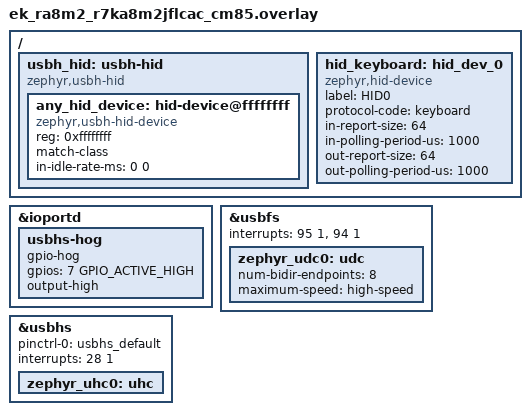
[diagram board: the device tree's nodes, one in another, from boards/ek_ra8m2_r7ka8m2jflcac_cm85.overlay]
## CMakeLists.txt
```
# Copyright (c) 2026 Renesas Electronics Corporation
# SPDX-License-Identifier: Apache-2.0

cmake_minimum_required(VERSION 3.20.0)

find_package(Zephyr REQUIRED HINTS $ENV{ZEPHYR_BASE})
project(test_usbh_hid)

include(${ZEPHYR_BASE}/samples/subsys/usb/common/common.cmake)

target_include_directories(app PRIVATE ${ZEPHYR_BASE}/tests/subsys/usb/host/common)
target_include_directories(app PRIVATE ${ZEPHYR_BASE}/subsys/usb/host)

target_sources(app PRIVATE src/keyboard.c src/hid_keyboard.c)
```

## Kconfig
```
# SPDX-FileCopyrightText: Copyright The Zephyr Project Contributors
# SPDX-License-Identifier: Apache-2.0

config SYS_CLOCK_TICKS_PER_SEC
	default 1000000 if BOARD_NATIVE_SIM

source "samples/subsys/usb/common/Kconfig.sample_usbd"

source "Kconfig.zephyr"
```

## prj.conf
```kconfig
CONFIG_LOG=y
CONFIG_ZTEST=y

CONFIG_USB_DEVICE_STACK_NEXT=y
CONFIG_USBD_HID_SUPPORT=y
CONFIG_UDC_ENABLE_SOF=y
CONFIG_SAMPLE_USBD_PID=0xFFFF

CONFIG_UHC_DRIVER=y
CONFIG_USB_HOST_STACK=y
```

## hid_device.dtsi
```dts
/*
 * SPDX-FileCopyrightText: Copyright The Zephyr Project Contributors
 * SPDX-License-Identifier: Apache-2.0
 */

/ {
	hid_dev_0: hid_dev_0 {
		compatible = "zephyr,hid-device";
		protocol-code = "none";
		in-report-size = <6>;
		in-polling-period-us = <1000>;
		/* Intentionally not a multiple of the UDC buffer granularity */
		out-report-size = <6>;
		out-polling-period-us = <1000>;
	};
};
```

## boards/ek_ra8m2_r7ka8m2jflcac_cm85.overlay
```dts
/*
 * Copyright (c) 2026 Renesas Electronics Corporation
 *
 *
 * SPDX-License-Identifier: Apache-2.0
 */

/delete-node/ &zephyr_udc0;

/ {
	usbh_hid: usbh-hid {
		compatible = "zephyr,usbh-hid";

		#address-cells = <1>;
		#size-cells = <0>;

		any_hid_device: hid-device@ffffffff {
			compatible = "zephyr,usbh-hid-device";
			reg = <0xffffffff>;
			match-class;
			in-idle-rate-ms = <0 0>;
			status = "okay";
		};
	};

	hid_keyboard: hid_dev_0 {
		compatible = "zephyr,hid-device";
		label = "HID0";
		protocol-code = "keyboard";
		in-report-size = <64>;
		in-polling-period-us = <1000>;
		out-report-size = <64>;
		out-polling-period-us = <1000>;
	};
};

&ioportd {
	status = "okay";

	/* Set PD07 to high to enable host mode on USBHS port */
	usbhs-hog {
		gpio-hog;
		gpios = <7 GPIO_ACTIVE_HIGH>;
		output-high;
	};
};

&usbfs {
	status = "okay";
	interrupts = <95 1>, <94 1>;
	interrupt-names = "usbfs-i", "usbfs-r";

	zephyr_udc0: udc {
		status = "okay";
		num-bidir-endpoints = <8>;
		maximum-speed = "high-speed";
	};
};

&usbhs {
	pinctrl-0 = <&usbhs_default>;
	interrupts = <28 1>;
	interrupt-names = "usbhs-ir";
	status = "okay";

	zephyr_uhc0: uhc {
		status = "okay";
	};
};
```

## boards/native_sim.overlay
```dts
/*
 * SPDX-FileCopyrightText: Copyright The Zephyr Project Contributors
 * SPDX-License-Identifier: Apache-2.0
 */

/delete-node/ &zephyr_udc0;

/ {
	zephyr_uhc0: uhc_vrt0 {
		compatible = "zephyr,uhc-virtual";

		zephyr_udc0: udc_vrt0 {
			compatible = "zephyr,udc-virtual";
			num-bidir-endpoints = <8>;
			maximum-speed = "high-speed";
		};
	};
};

#include "../hid_device.dtsi"
```

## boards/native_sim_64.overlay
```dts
/*
 * Copyright (c) 2026 Renesas Electronics Corporation
 *
 * SPDX-License-Identifier: Apache-2.0
 */

#include "native_sim.overlay"
```

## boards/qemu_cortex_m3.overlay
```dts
/*
 * SPDX-FileCopyrightText: Copyright The Zephyr Project Contributors
 * SPDX-License-Identifier: Apache-2.0
 */

/ {
	zephyr_uhc0: uhc_vrt0 {
		compatible = "zephyr,uhc-virtual";

		zephyr_udc0: udc_vrt0 {
			compatible = "zephyr,udc-virtual";
			num-bidir-endpoints = <8>;
			maximum-speed = "high-speed";
		};
	};
};

#include "../hid_device.dtsi"
```

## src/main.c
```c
/*
 * SPDX-FileCopyrightText: Copyright The Zephyr Project Contributors
 * SPDX-License-Identifier: Apache-2.0
 */

#include <sample_usbd.h>

#include <zephyr/ztest.h>
#include <zephyr/usb/usbd.h>
#include <zephyr/usb/usbh.h>
#include <zephyr/usb/class/usbd_hid.h>

#include <usbh_desc.h>
#include <usbh_device.h>

#include <zephyr/logging/log.h>
LOG_MODULE_REGISTER(usb_test, LOG_LEVEL_INF);

#define TEST_REPORT_SIZE	DT_PROP(DT_NODELABEL(hid_dev_0), out_report_size)

static const uint8_t test_report_desc[] = {
	HID_USAGE_PAGE16(0xFF00),
	HID_USAGE(0x01),
	HID_COLLECTION(HID_COLLECTION_APPLICATION),
		HID_USAGE(0x02),
		HID_LOGICAL_MIN8(0),
		HID_LOGICAL_MAX16(0xFF, 0x00),
		HID_REPORT_SIZE(8),
		HID_REPORT_COUNT(TEST_REPORT_SIZE),
		HID_INPUT(0x02),
		HID_USAGE(0x03),
		HID_OUTPUT(0x02),
	HID_END_COLLECTION,
};

struct test_report {
	uint16_t len;
	uint8_t data[2 * TEST_REPORT_SIZE];
};

K_MSGQ_DEFINE(test_report_msgq, sizeof(struct test_report), 4, 4);
static K_SEM_DEFINE(test_xfer_sem, 0, 1);
static int test_xfer_err;
static uint8_t test_out_ep;

static struct usbd_context *test_usbd;

USBH_CONTROLLER_DEFINE(uhs_ctx, DEVICE_DT_GET(DT_NODELABEL(zephyr_uhc0)));

static int test_get_report(const struct device *dev,
			   const uint8_t type, const uint8_t id,
			   const uint16_t len, uint8_t *const buf)
{
	return -ENOTSUP;
}

static int test_set_report(const struct device *dev,
			   const uint8_t type, const uint8_t id,
			   const uint16_t len, const uint8_t *const buf)
{
	return -ENOTSUP;
}

static void test_output_report(const struct device *dev,
			       const uint16_t len, const uint8_t *const buf)
{
	struct test_report report = {
		.len = len,
	};

	memcpy(report.data, buf, MIN(len, sizeof(report.data)));
	(void)k_msgq_put(&test_report_msgq, &report, K_NO_WAIT);
}

static const struct hid_device_ops test_hid_ops = {
	.get_report = test_get_report,
	.set_report = test_set_report,
	.output_report = test_output_report,
};

static int test_xfer_cb(struct usb_device *const udev,
			struct uhc_transfer *const xfer)
{
	test_xfer_err = xfer->err;

	if (xfer->buf != NULL) {
		usbh_xfer_buf_free(udev, xfer->buf);
	}

	(void)uhc_xfer_unref(xfer);
	k_sem_give(&test_xfer_sem);

	return 0;
}

static uint8_t test_get_out_ep(const struct usb_device *const udev)
{
	const struct usb_cfg_descriptor *const c_desc = udev->cfg_desc;

	if (c_desc == NULL) {
		return 0;
	}

	for (unsigned int i = 0; i < c_desc->bNumInterfaces; i++) {
		const struct usb_if_descriptor *const if_d = (void *)udev->ifaces[i].dhp;
		const struct usb_desc_header *desc;

		if (if_d == NULL || if_d->bInterfaceClass != USB_BCC_HID) {
			continue;
		}

		desc = usbh_desc_get_next(if_d);
		while (desc != NULL && desc->bDescriptorType != USB_DESC_INTERFACE) {
			const struct usb_ep_descriptor *const ep_d = (void *)desc;

			if (desc->bDescriptorType == USB_DESC_ENDPOINT &&
			    USB_EP_DIR_IS_OUT(ep_d->bEndpointAddress)) {
				return ep_d->bEndpointAddress;
			}

			desc = usbh_desc_get_next(desc);
		}
	}

	return 0;
}

static void test_send_report(const uint8_t *const data)
{
	struct usb_device *udev;
	struct uhc_transfer *xfer;
	struct net_buf *buf;
	int err;

	udev = usbh_device_get_any(&uhs_ctx);
	zassert_not_null(udev, "No USB device available");

	xfer = usbh_xfer_alloc(udev, test_out_ep, test_xfer_cb, NULL);
	zassert_not_null(xfer, "Failed to allocate transfer");

	buf = usbh_xfer_buf_alloc(udev, TEST_REPORT_SIZE);
	zassert_not_null(buf, "Failed to allocate buffer");

	net_buf_add_mem(buf, data, TEST_REPORT_SIZE);
	xfer->buf = buf;

	err = usbh_xfer_enqueue(udev, xfer);
	zassert_equal(err, 0, "Failed to enqueue transfer");

	err = k_sem_take(&test_xfer_sem, K_MSEC(500));
	zassert_equal(err, 0, "Transfer timeout");
	zassert_equal(test_xfer_err, 0, "Transfer status is an error");
}

static void test_check_report(const uint8_t *const data)
{
	struct test_report report;
	int err;

	err = k_msgq_get(&test_report_msgq, &report, K_MSEC(500));
	zassert_equal(err, 0, "No output report received");
	zassert_equal(report.len, TEST_REPORT_SIZE, "Output report length mismatch");
	zassert_mem_equal(report.data, data, TEST_REPORT_SIZE,
			  "Output report data mismatch");
}

/* An output report is received in one transfer of the report size */
ZTEST(usb_hid, test_output_report)
{
	const uint8_t data[TEST_REPORT_SIZE] = {0x10, 0x11, 0x12, 0x13, 0x14, 0x15};

	test_send_report(data);
	test_check_report(data);
}

/* Consecutive output reports are received separately and in order */
ZTEST(usb_hid, test_output_reports)
{
	const uint8_t data1[TEST_REPORT_SIZE] = {0x20, 0x21, 0x22, 0x23, 0x24, 0x25};
	const uint8_t data2[TEST_REPORT_SIZE] = {0x30, 0x31, 0x32, 0x33, 0x34, 0x35};

	test_send_report(data1);
	test_send_report(data2);
	test_check_report(data1);
	test_check_report(data2);
}

static void *usb_test_enable(void)
{
	struct usb_device *udev;
	int err;

	err = usbh_init(&uhs_ctx);
	zassert_equal(err, 0, "Failed to initialize USB host");

	err = usbh_enable(&uhs_ctx);
	zassert_equal(err, 0, "Failed to enable USB host");

	err = uhc_bus_reset(uhs_ctx.dev);
	zassert_equal(err, 0, "Failed to signal bus reset");

	err = uhc_bus_resume(uhs_ctx.dev);
	zassert_equal(err, 0, "Failed to signal bus resume");

	err = uhc_sof_enable(uhs_ctx.dev);
	zassert_equal(err, 0, "Failed to enable SoF generator");

	err = hid_device_register(DEVICE_DT_GET(DT_NODELABEL(hid_dev_0)),
				  test_report_desc, sizeof(test_report_desc),
				  &test_hid_ops);
	zassert_equal(err, 0, "Failed to register HID device (%d)", err);

	test_usbd = sample_usbd_init_device(NULL);
	zassert_not_null(test_usbd, "Failed to initialize USB device");

	err = usbd_enable(test_usbd);
	zassert_equal(err, 0, "Failed to enable device support");

	/* Allow the host time to reset the device. */
	k_msleep(200);

	udev = usbh_device_get_any(&uhs_ctx);
	zassert_not_null(udev, "No USB device available");

	test_out_ep = test_get_out_ep(udev);
	zassert_not_equal(test_out_ep, 0, "No HID interrupt OUT endpoint");

	return NULL;
}

static void usb_test_before(void *f)
{
	k_msgq_purge(&test_report_msgq);
}

static void usb_test_shutdown(void *f)
{
	int err;

	err = usbd_disable(test_usbd);
	zassert_equal(err, 0, "Failed to disable device support");

	err = usbd_shutdown(test_usbd);
	zassert_equal(err, 0, "Failed to shutdown device support");

	err = usbh_disable(&uhs_ctx);
	zassert_equal(err, 0, "Failed to disable USB host");
}

ZTEST_SUITE(usb_hid, NULL, usb_test_enable, usb_test_before, NULL, usb_test_shutdown);
```

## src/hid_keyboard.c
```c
/*
 * Copyright (c) 2026 Renesas Electronics Corporation
 *
 * SPDX-License-Identifier: Apache-2.0
 */

#include <string.h>

#include <zephyr/ztest.h>
#include <zephyr/kernel.h>
#include <zephyr/device.h>
#include <zephyr/drivers/gpio.h>
#include <zephyr/input/input.h>
#include <zephyr/usb/usbd.h>
#include <zephyr/usb/class/usbd_hid.h>

#include "hid_keyboard.h"

static const uint8_t hid_report_desc[] = HID_KEYBOARD_REPORT_DESC();

static uint32_t kb_duration;
static uint8_t report_value;
/* 0 for a successful (dummy) Get Report reply, a negative errno to make the device stall */
static int get_report_error;

static void kb_iface_ready(const struct device *dev, const bool ready)
{
}

static int kb_get_report(const struct device *dev, const uint8_t type, const uint8_t id,
			 const uint16_t len, uint8_t *const buf)
{
	if (get_report_error != 0) {
		return get_report_error;
	}

	/* A real device would fill `buf` with the current value of the requested report;
	 * a dummy, zeroed one is enough to exercise a successful transfer.
	 */
	memset(buf, 0, len);

	return len;
}

static int kb_set_report(const struct device *dev, const uint8_t type, const uint8_t id,
			 const uint16_t len, const uint8_t *const buf)
{
	if (type != HID_REPORT_TYPE_OUTPUT) {
		return -ENOTSUP;
	}

	return 0;
}

/* Idle duration is stored but not used to calculate idle reports. */
static void kb_set_idle(const struct device *dev, const uint8_t id, const uint32_t duration)
{
	kb_duration = duration;
}

static uint32_t kb_get_idle(const struct device *dev, const uint8_t id)
{
	return kb_duration;
}

static void kb_set_protocol(const struct device *dev, const uint8_t proto)
{
}

static void kb_output_report(const struct device *dev, const uint16_t len, const uint8_t *const buf)
{
	zassert_equal(1, len, "Wrong report length");
	kb_set_report(dev, HID_REPORT_TYPE_OUTPUT, 0u, len, buf);
	report_value = buf[0];
}

static struct hid_device_ops kb_ops = {
	.iface_ready = kb_iface_ready,
	.get_report = kb_get_report,
	.set_report = kb_set_report,
	.set_idle = kb_set_idle,
	.get_idle = kb_get_idle,
	.set_protocol = kb_set_protocol,
	.output_report = kb_output_report,
};

int hid_keyboard_register(void)
{
	const struct device *hid_dev = DEVICE_DT_GET(DT_NODELABEL(hid_keyboard));
	int result = 0;

	if (!device_is_ready(hid_dev)) {
		return -EIO;
	}

	result = hid_device_register(hid_dev, hid_report_desc, sizeof(hid_report_desc), &kb_ops);
	if (result != 0) {
		return result;
	}

	return 0;
}

uint8_t hid_keyboard_get_report_value(void)
{
	return report_value;
}

void hid_keyboard_set_get_report_error(int error)
{
	get_report_error = error;
}

void hid_keyboard_set_idle_supported(bool supported)
{
	kb_ops.set_idle = supported ? kb_set_idle : NULL;
}
```

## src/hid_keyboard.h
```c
/*
 * Copyright (c) 2026 Renesas Electronics Corporation
 *
 * SPDX-License-Identifier: Apache-2.0
 */

#ifndef HID_KEYBOARD_H_INCLUDED
#define HID_KEYBOARD_H_INCLUDED

#include <stdbool.h>
#include <stdint.h>

int hid_keyboard_register(void);
uint8_t hid_keyboard_get_report_value(void);

/**
 * @brief Configure the result the emulated keyboard's Get Report handler should give
 *
 * @param error 0 for a successful (dummy) report, a negative errno value to make the
 *              device reject (stall) the next Get Report requests
 */
void hid_keyboard_set_get_report_error(int error);

/**
 * @brief Configure whether the emulated keyboard advertises Set Idle support
 *
 * @param supported false to make the device reject (stall) Set Idle requests
 */
void hid_keyboard_set_idle_supported(bool supported);

#endif /* HID_KEYBOARD_H_INCLUDED */
```

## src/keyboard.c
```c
/*
 * Copyright (c) 2026 Renesas Electronics Corporation
 *
 * SPDX-License-Identifier: Apache-2.0
 */

#include <zephyr/ztest.h>
#include <zephyr/usb/usbd.h>
#include <zephyr/usb/class/hid.h>
#include <zephyr/logging/log.h>
#include <zephyr/input/input.h>
#include <sample_usbd.h>
#include <zephyr/usb/class/usbd_hid.h>
#include <zephyr/usb/class/usbh_hid.h>

#include "usbh_desc.h"
#include "usbh_device.h"
#include "hid_keyboard.h"

LOG_MODULE_REGISTER(usbh_test_hid, LOG_LEVEL_INF);

#define MAX_EVENTS 16

struct usbh_hid_keyboard_suite_fixture {
	size_t expected_events_index;
	struct input_event expected_events[MAX_EVENTS];
	size_t expected_usages_index;
	uint8_t expected_usages[MAX_EVENTS];
	struct k_sem input_sync;
	struct k_sem report_sync;
};

static struct device const *hid_dev = DEVICE_DT_GET(DT_NODELABEL(hid_keyboard));
static struct device const *usbh_hid_dev = DEVICE_DT_GET(DT_NODELABEL(any_hid_device));
static struct usbd_context *test_usbd;

USBH_CONTROLLER_DEFINE(test_uhs_ctx, DEVICE_DT_GET(DT_NODELABEL(zephyr_uhc0)));

struct usbh_context *const uhs_ctx = &test_uhs_ctx;

static struct usbh_hid_keyboard_suite_fixture fixture = {};

static void *suite_setup(void)
{
	int result = 0;

	k_sem_init(&fixture.input_sync, 0, 1);
	k_sem_init(&fixture.report_sync, 0, 1);

	result = usbh_init(uhs_ctx);
	zassert_ok(result, "Failed to initialize USB host");

	result = usbh_enable(uhs_ctx);
	zassert_ok(result, "Failed to enable USB host");

	result = uhc_bus_reset(uhs_ctx->dev);
	zassert_ok(result, "Failed to signal bus reset");

	result = uhc_bus_resume(uhs_ctx->dev);
	zassert_ok(result, "Failed to signal bus resume");

	result = uhc_sof_enable(uhs_ctx->dev);
	zassert_ok(result, "Failed to enable SoF generator");

	result = hid_keyboard_register();
	zassert_ok(result, "Failed to register HID device");

	test_usbd = sample_usbd_setup_device(NULL);
	zassert_not_null(test_usbd, "Failed to setup USB device");

	result = usbd_init(test_usbd);
	zassert_ok(result, "Failed to initialize device support");

	result = usbd_enable(test_usbd);
	zassert_ok(result, "Failed to enable device support");

	/* Allow the host time to reset the device. */
	k_msleep(1000);

	result = usbh_hid_start_input_reports(usbh_hid_dev);
	zassert_ok(result, "Failed to start input reports");

	return NULL;
}

static void suite_shutdown(void *f)
{
	int result = 0;

	result = usbd_disable(test_usbd);
	zassert_ok(result, "Failed to disable device support");

	result = usbd_shutdown(test_usbd);
	zassert_ok(result, "Failed to shutdown device support");

	result = usbh_disable(uhs_ctx);
	zassert_ok(result, "Failed to disable USB host");

	result = usbh_shutdown(uhs_ctx);
	zassert_ok(result, "Failed to shutdown host support");
}

ZTEST_SUITE(usbh_hid_keyboard_suite, NULL, suite_setup, NULL, NULL, suite_shutdown);

ZTEST(usbh_hid_keyboard_suite, test_usbh_hid_keyboard_set_protocol)
{
	int result = 0;
	uint8_t protocol_code = 0;

	result = usbh_hid_set_protocol(usbh_hid_dev, HID_PROTOCOL_BOOT);
	zassert_ok(result, "Unable to set protocol");

	result = usbh_hid_get_protocol(usbh_hid_dev, &protocol_code);
	zassert_ok(result, "Unable to get protocol");
	zassert_equal(protocol_code, HID_PROTOCOL_BOOT, "Wrong protocol");

	result = usbh_hid_set_protocol(usbh_hid_dev, HID_PROTOCOL_REPORT);
	zassert_ok(result, "Unable to set protocol");

	result = usbh_hid_get_protocol(usbh_hid_dev, &protocol_code);
	zassert_ok(result, "Unable to get protocol");
	zassert_equal(protocol_code, HID_PROTOCOL_REPORT, "Wrong protocol");
}

ZTEST(usbh_hid_keyboard_suite, test_usbh_hid_keyboard_output_report)
{
	uint8_t const report[] = {0xF};
	int result = 0;

	result = usbh_hid_set_report(usbh_hid_dev, HID_REPORT_TYPE_OUTPUT, 0, sizeof(report),
				     report);
	zassert_ok(result, "Unable to set report");

	zassert_equal(report[0], hid_keyboard_get_report_value(), "Wrong report value");
}

ZTEST(usbh_hid_keyboard_suite, test_usbh_hid_keyboard_set_idle)
{
	int result = 0;
	uint16_t idle_period_ms = 0;

	/* Idle period must be a multiple of 4 */
	result = usbh_hid_set_idle_rate(usbh_hid_dev, 0, 501u);
	zassert_equal(result, -EINVAL, "Idle periods not divisible by 4 should be rejected");

	result = usbh_hid_set_idle_rate(usbh_hid_dev, 0, 255u * 4u + 1u);
	zassert_equal(result, -EINVAL,
		      "Idle periods beyond what fits in a byte should be rejected");

	result = usbh_hid_set_idle_rate(usbh_hid_dev, 0, 500u);
	zassert_ok(result, "Failed to set idle rate");

	result = usbh_hid_get_idle_rate(usbh_hid_dev, 0, &idle_period_ms);
	zassert_ok(result, "Failed to set idle rate");
	zassert_equal(idle_period_ms, 500u, "Wrong idle rate");

	result = usbh_hid_set_idle_rate(usbh_hid_dev, 0, 0u);
	zassert_ok(result, "Failed to set idle rate");

	result = usbh_hid_get_idle_rate(usbh_hid_dev, 0, &idle_period_ms);
	zassert_ok(result, "Failed to set idle rate");
	zassert_equal(idle_period_ms, 0u, "Wrong idle rate");
}

int input_report_cb(struct usbh_hid_report_field const *field, uint8_t report_id,
		    size_t data_length, uint8_t const *data, size_t bit_index, void *user_data)
{
	size_t value_index = bit_index / 8;
	uint8_t const *value_ptr = &data[value_index];
	struct usbh_hid_keyboard_suite_fixture *fixture_ptr = user_data;

	zassert_equal(fixture_ptr, &fixture, "Invalid user data");

	if (usbh_hid_report_match_usage_page(field, HID_USAGE_GEN_KEYBOARD)) {
		/* Array data, each non-zero key is a usage id */
		if (USBH_HID_REPORT_DATA_IS_ARRAY(field->flags) && field->size == 8) {
			for (size_t key_index = 0; key_index < field->count; key_index++) {
				uint8_t usage_id = value_ptr[key_index];

				if (usage_id != 0) {
					uint16_t expected_usage =
						fixture_ptr->expected_usages
							[fixture_ptr->expected_usages_index];

					zassert_equal(usage_id, expected_usage,
						      "Invalid usage: expected 0x%X, found 0x%X",
						      expected_usage, usage_id);
					fixture_ptr->expected_usages_index++;

					if (fixture_ptr->expected_usages
						    [fixture_ptr->expected_usages_index] == 0) {
						k_sem_give(&fixture_ptr->report_sync);
					}
				}
			}
		} else if (USBH_HID_REPORT_DATA_IS_VARIABLE(field->flags) && field->size == 1u) {
			/* Variable data, a bitset where the position indicates the usage id */
			for (size_t key_position = 0; key_position < field->count; key_position++) {
				size_t key_index = key_position / 8;
				size_t key_shift = key_position % 8;
				uint16_t usage_id = usbh_hid_report_field_get_usage_id_by_index(
					field, key_position);

				if ((value_ptr[key_index] & (1 << key_shift)) > 0) {
					uint16_t expected_usage =
						fixture_ptr->expected_usages
							[fixture_ptr->expected_usages_index];

					zassert_equal(usage_id, expected_usage,
						      "Invalid usage: expected 0x%X, found 0x%X",
						      expected_usage, usage_id);
					fixture_ptr->expected_usages_index++;

					if (fixture_ptr->expected_usages
						    [fixture_ptr->expected_usages_index] == 0) {
						k_sem_give(&fixture_ptr->report_sync);
					}
				}
			}
		}
	}

	return 0;
}

ZTEST(usbh_hid_keyboard_suite, test_usbh_hid_keyboard_input_single_keys)
{
	uint8_t control_usage = 0xE0;
	const uint8_t x_usage = 0x1B;
	int result = 0;

	result = usbh_hid_set_input_callback(usbh_hid_dev, input_report_cb, &fixture);
	zassert_ok(result);

	{
		/* X button press */
		uint8_t report[] = {0, 0, x_usage, 0, 0, 0, 0, 0};

		memset(fixture.expected_events, 0, sizeof(fixture.expected_events));
		fixture.expected_events_index = 0;
		fixture.expected_events[0].type = INPUT_EV_KEY;
		fixture.expected_events[0].code = INPUT_KEY_X;
		fixture.expected_events[0].value = 1;

		fixture.expected_usages_index = 0;
		memset(fixture.expected_usages, 0, sizeof(fixture.expected_usages));
		fixture.expected_usages[0] = x_usage;

		hid_device_submit_report(hid_dev, sizeof(report), report);
		k_sem_take(&fixture.input_sync, K_FOREVER);
		k_sem_take(&fixture.report_sync, K_FOREVER);
	}

	{
		/* X button release */
		uint8_t report[] = {0, 0, 0, 0, 0, 0, 0, 0};

		memset(fixture.expected_events, 0, sizeof(fixture.expected_events));
		fixture.expected_events_index = 0;
		fixture.expected_events[0].type = INPUT_EV_KEY;
		fixture.expected_events[0].code = INPUT_KEY_X;
		fixture.expected_events[0].value = 0;

		fixture.expected_usages_index = 0;
		memset(fixture.expected_usages, 0, sizeof(fixture.expected_usages));

		hid_device_submit_report(hid_dev, sizeof(report), report);
		k_sem_take(&fixture.input_sync, K_FOREVER);

		/* No usages, no semaphore give */
		zassert_not_ok(k_sem_take(&fixture.report_sync, K_MSEC(100)));
	}

	{
		/* Left control modifier press */
		uint8_t report[] = {1, 0, 0, 0, 0, 0, 0, 0};

		memset(fixture.expected_events, 0, sizeof(fixture.expected_events));
		fixture.expected_events_index = 0;
		fixture.expected_events[0].type = INPUT_EV_KEY;
		fixture.expected_events[0].code = INPUT_KEY_LEFTCTRL;
		fixture.expected_events[0].value = 1;

		fixture.expected_usages_index = 0;
		memset(fixture.expected_usages, 0, sizeof(fixture.expected_usages));
		fixture.expected_usages[0] = control_usage;

		hid_device_submit_report(hid_dev, sizeof(report), report);
		k_sem_take(&fixture.input_sync, K_FOREVER);
		k_sem_take(&fixture.report_sync, K_FOREVER);
	}

	{
		/* Left control modifier release */
		uint8_t report[] = {0, 0, 0, 0, 0, 0, 0, 0};

		memset(fixture.expected_events, 0, sizeof(fixture.expected_events));
		fixture.expected_events_index = 0;
		fixture.expected_events[0].type = INPUT_EV_KEY;
		fixture.expected_events[0].code = INPUT_KEY_LEFTCTRL;
		fixture.expected_events[0].value = 0;

		fixture.expected_usages_index = 0;
		memset(fixture.expected_usages, 0, sizeof(fixture.expected_usages));

		hid_device_submit_report(hid_dev, sizeof(report), report);
		k_sem_take(&fixture.input_sync, K_FOREVER);

		/* No usages, no semaphore give */
		zassert_not_ok(k_sem_take(&fixture.report_sync, K_MSEC(100)));
	}
}

ZTEST(usbh_hid_keyboard_suite, test_usbh_hid_keyboard_input_multiple_keys)
{
	uint8_t control_usage = 0xE0;
	const uint8_t x_usage = 0x1B;
	const uint8_t y_usage = 0x1C;
	int result = 0;

	result = usbh_hid_set_input_callback(usbh_hid_dev, input_report_cb, &fixture);
	zassert_ok(result);

	{
		/* Left control, X and Y press */
		uint8_t report[] = {1, 0, x_usage, y_usage, 0, 0, 0, 0};

		memset(fixture.expected_events, 0, sizeof(fixture.expected_events));
		fixture.expected_events_index = 0;
		fixture.expected_events[0].type = INPUT_EV_KEY;
		fixture.expected_events[0].code = INPUT_KEY_LEFTCTRL;
		fixture.expected_events[0].value = 1;

		fixture.expected_events[1].type = INPUT_EV_KEY;
		fixture.expected_events[1].code = INPUT_KEY_X;
		fixture.expected_events[1].value = 1;

		fixture.expected_events[2].type = INPUT_EV_KEY;
		fixture.expected_events[2].code = INPUT_KEY_Y;
		fixture.expected_events[2].value = 1;

		fixture.expected_usages_index = 0;
		memset(fixture.expected_usages, 0, sizeof(fixture.expected_usages));
		fixture.expected_usages[0] = control_usage;
		fixture.expected_usages[1] = x_usage;
		fixture.expected_usages[2] = y_usage;

		hid_device_submit_report(hid_dev, sizeof(report), report);
		k_sem_take(&fixture.input_sync, K_FOREVER);
		k_sem_take(&fixture.report_sync, K_FOREVER);
	}

	{
		/* X release */
		uint8_t report[] = {1, 0, 0x1C, 0, 0, 0, 0, 0};

		memset(fixture.expected_events, 0, sizeof(fixture.expected_events));
		fixture.expected_events_index = 0;
		fixture.expected_events[0].type = INPUT_EV_KEY;
		fixture.expected_events[0].code = INPUT_KEY_LEFTCTRL;
		fixture.expected_events[0].value = 1;

		fixture.expected_events[1].type = INPUT_EV_KEY;
		fixture.expected_events[1].code = INPUT_KEY_Y;
		fixture.expected_events[1].value = 1;

		fixture.expected_events[2].type = INPUT_EV_KEY;
		fixture.expected_events[2].code = INPUT_KEY_X;
		fixture.expected_events[2].value = 0;

		fixture.expected_usages_index = 0;
		memset(fixture.expected_usages, 0, sizeof(fixture.expected_usages));
		fixture.expected_usages[0] = control_usage;
		fixture.expected_usages[1] = y_usage;

		hid_device_submit_report(hid_dev, sizeof(report), report);
		k_sem_take(&fixture.input_sync, K_FOREVER);
		k_sem_take(&fixture.report_sync, K_FOREVER);
	}

	{
		/* Left control and Y release */
		uint8_t report[] = {0, 0, 0, 0, 0, 0, 0, 0};

		memset(fixture.expected_events, 0, sizeof(fixture.expected_events));
		fixture.expected_events_index = 0;
		fixture.expected_events[0].type = INPUT_EV_KEY;
		fixture.expected_events[0].code = INPUT_KEY_LEFTCTRL;
		fixture.expected_events[0].value = 0;

		fixture.expected_events[1].type = INPUT_EV_KEY;
		fixture.expected_events[1].code = INPUT_KEY_Y;
		fixture.expected_events[1].value = 0;

		fixture.expected_usages_index = 0;
		memset(fixture.expected_usages, 0, sizeof(fixture.expected_usages));

		hid_device_submit_report(hid_dev, sizeof(report), report);
		k_sem_take(&fixture.input_sync, K_FOREVER);

		/* No usages, no semaphore give */
		zassert_not_ok(k_sem_take(&fixture.report_sync, K_MSEC(100)));
	}
}

/*
 * The following tests exercise error paths of the usbh_hid public API by making the emulated
 * keyboard give an invalid or unsupported response to the host's request.
 */

ZTEST(usbh_hid_keyboard_suite, test_usbh_hid_keyboard_get_report_descriptor_invalid_args)
{
	int result = usbh_hid_get_report_descriptor(usbh_hid_dev, NULL);

	zassert_equal(-EINVAL, result, "A NULL report pointer should be rejected");
}

ZTEST(usbh_hid_keyboard_suite, test_usbh_hid_keyboard_get_report)
{
	uint8_t buffer[8] = {0xFFu, 0xFFu, 0xFFu, 0xFFu, 0xFFu, 0xFFu, 0xFFu, 0xFFu};
	int result = 0;

	hid_keyboard_set_get_report_error(0);
	result =
		usbh_hid_get_report(usbh_hid_dev, HID_REPORT_TYPE_INPUT, 0, sizeof(buffer), buffer);
	zassert_ok(result, "Unable to get report");
	for (size_t i = 0; i < sizeof(buffer); i++) {
		zassert_equal(0, buffer[i], "Wrong report content");
	}

	/* The device rejects the request; this should surface as a stalled transfer */
	hid_keyboard_set_get_report_error(-EIO);
	result =
		usbh_hid_get_report(usbh_hid_dev, HID_REPORT_TYPE_INPUT, 0, sizeof(buffer), buffer);
	zassert_equal(-EPIPE, result, "A rejected Get Report should be surfaced as a stall");

	hid_keyboard_set_get_report_error(0);
}

ZTEST(usbh_hid_keyboard_suite, test_usbh_hid_keyboard_set_idle_invalid_report_id)
{
	int result = 0;
	uint16_t idle_period_ms = 0;

	/* This device's report descriptor declares no report variants,
	 * so any ID but 0 is invalid.
	 */
	result = usbh_hid_set_idle_rate(usbh_hid_dev, 0x7Fu, 100u);
	zassert_equal(-EINVAL, result, "Nonexistend report ID not rejected");

	result = usbh_hid_get_idle_rate(usbh_hid_dev, 0x7Fu, &idle_period_ms);
	zassert_equal(-EINVAL, result, "Nonexistend report ID not rejected");
}

ZTEST(usbh_hid_keyboard_suite, test_usbh_hid_keyboard_set_idle_not_supported)
{
	int result = 0;

	hid_keyboard_set_idle_supported(false);

	result = usbh_hid_set_idle_rate(usbh_hid_dev, 0, 100u);
	zassert_equal(-EPIPE, result, "Unsupported SET_IDLE operation didn't stall");

	hid_keyboard_set_idle_supported(true);

	result = usbh_hid_set_idle_rate(usbh_hid_dev, 0, 0u);
	zassert_ok(result, "Failed to restore the idle rate");
}

ZTEST(usbh_hid_keyboard_suite, test_usbh_hid_keyboard_set_protocol_invalid_code)
{
	int result = 0;
	uint8_t protocol_code = 0;

	result = usbh_hid_set_protocol(usbh_hid_dev, HID_PROTOCOL_REPORT);
	zassert_ok(result, "Unable to set protocol");

	/* Only HID_PROTOCOL_BOOT (0) and HID_PROTOCOL_REPORT (1) are valid */
	result = usbh_hid_set_protocol(usbh_hid_dev, 2u);
	zassert_equal(-EPIPE, result, "An out-of-range protocol code should be rejected");

	/* The device should still be reporting the last protocol it actually accepted */
	result = usbh_hid_get_protocol(usbh_hid_dev, &protocol_code);
	zassert_ok(result, "Unable to get protocol");
	zassert_equal(protocol_code, HID_PROTOCOL_REPORT, "Wrong protocol");
}

ZTEST(usbh_hid_keyboard_suite, test_usbh_hid_keyboard_set_report_invalid_args)
{
	uint8_t const report[] = {0x00u};
	int result = 0;

	result = usbh_hid_set_report(usbh_hid_dev, HID_REPORT_TYPE_OUTPUT, 0, 0, NULL);
	zassert_equal(-EINVAL, result, "NULL report was accepted");

	result = usbh_hid_set_report(usbh_hid_dev, HID_REPORT_TYPE_OUTPUT, 0, 0, report);
	zassert_equal(-EINVAL, result, "Zero-length report was accepted");
}

static void verify_input_cb(struct input_event *evt, void *user_data)
{
	zassert_equal(fixture.expected_events[fixture.expected_events_index].type, evt->type,
		      "Wrong input event type");
	zassert_equal(fixture.expected_events[fixture.expected_events_index].code, evt->code,
		      "Wrong input event code");
	zassert_equal(fixture.expected_events[fixture.expected_events_index].value, evt->value,
		      "Wrong input event value");

	fixture.expected_events_index++;

	if (fixture.expected_events[fixture.expected_events_index].type == 0u) {
		k_sem_give(&fixture.input_sync);
	}
}

INPUT_CALLBACK_DEFINE(NULL, verify_input_cb, NULL);
```
